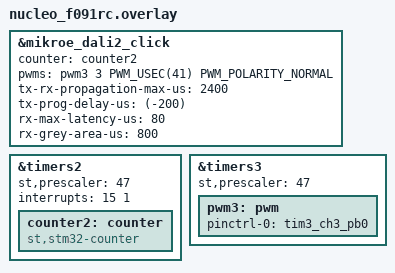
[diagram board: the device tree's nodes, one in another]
/*
 * Copyright 2026 by Sven Hädrich <sven.haedrich@sevenlab.de>
 * SPDX-License-Identifier: Apache-2.0
 *
 * add DALI 2 Click (MIKROE-2672)
 * via Arduino UNO click shield (MIKROE-1581)
 * to STM32 NUCLEO F091RC
 * DALI 2 Click
 *   DALI TX 2
 *   DALI RX 15
 * Arduino UNO click shield (slot 1)
 *   DALI TX 2 > A3
 *   DALI RX 15 > D2
 * STM32F091
 *   DALI TX A3 > PB_0
 *   DALI RX D2 > PA_10
 */

&mikroe_dali2_click {
	counter = <&counter2>;
	pwms = <&pwm3 3 PWM_USEC(41) PWM_POLARITY_NORMAL>;
	tx-rx-propagation-max-us = <2400>;
	tx-prog-delay-us = <(-200)>;
	rx-max-latency-us = <80>;
	rx-grey-area-us = <800>;
};

&timers2 {
	// set timebase to 1us/1MHz
	st,prescaler = <47>;
	status = "okay";
	interrupts = <15 1>;

	counter2: counter {
		compatible = "st,stm32-counter";
		status = "okay";
	};
};

&timers3 {
	// set timebase to 1us/1MHz
	st,prescaler = <47>;
	status = "okay";

	pwm3: pwm {
		pinctrl-0 = <&tim3_ch3_pb0>; // microbus header 1
		pinctrl-names = "default";
		status = "okay";
	};
};
